# dm648_cslr_aemif register map
Vendor: Texas Instruments
Peripheral module from a debugger description file.
Registers are 32-bit, access not given, reset 0x0 unless marked. A register's access mark holds for its fields unless they carry their own. Offsets are as the file gives them; lines under a group give offsets from that group; [hi:lo] are bit positions; {n}, {i} and the like mark numbered series; 'fields as' and 'values as' point back to an identical list; <NAME> marks a mode.

## AEMIF — This module provides an interface between TI DSP device and SRAM devices
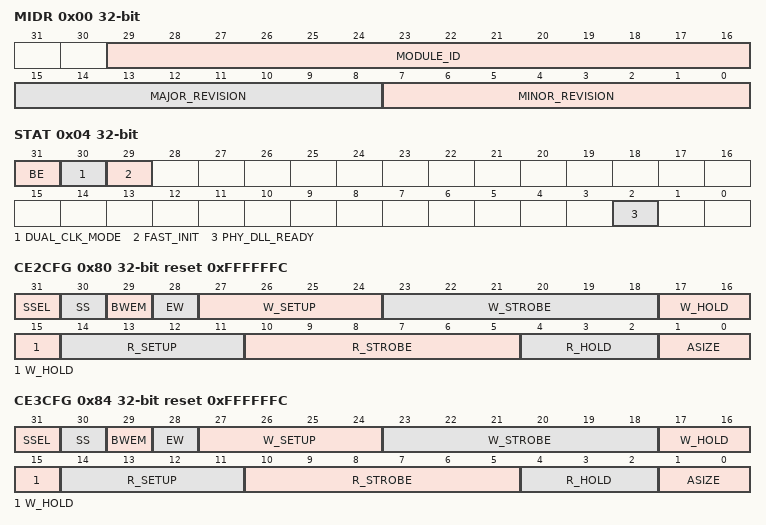
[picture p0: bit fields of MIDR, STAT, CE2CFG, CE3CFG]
0x00 MIDR — This register reflects the latest changes made to the memory controller.
  [29:16] MODULE_ID ro — EMIF module ID
  [15:8] MAJOR_REVISION ro
  [7:0] MINOR_REVISION ro
0x04 STAT — This register reflects the SDRAM status
  [31] BE ro — Big Endian. Reflects the value on the big_endian port that defines whether the EMIF is in big or little endian mode.
    1=B_ENDIAN (Big Endian); 0=L_ENDIAN (Little Endian)
  [30] DUAL_CLK_MODE ro — Dual Clock mode. Reflects the value on the dual_clk_mode port that defines whether the vclk and mclk inputs are asynchronous.
    1=ASYNC (vclk and mclk inputs are asynchronous.); 0=SYNC (vclk and mclk inputs are synchronous.)
  [29] FAST_INIT ro — the value on the fast_init port that defines whether the EMIF fast initialization mode has been enabled.
    0=NORMAL (normal operation); 1=TEST (running SDRAM functional tests.)
  [2] PHY_DLL_READY ro — DDR PHY Ready. Reflects the value on the phy_ready port (active high) that defines whether the DDR PHY is ready for normal operation.
    0=DEASSERTED (Signal deasserted); 1=ASSERTED (Signal asserted)
0x20 BPRIO reset 0xFF — Priority Raise Old Counter.
  [7:0] PR_OLD_COUNT rw — Number of memory transfers after which the EMIF momentarily raises the priority of oldcommands in the VBUSM Command FIFO.
0x80 CE2CFG rw reset 0xFFFFFFC — CS2 ASYNC Emif Register
  [31] SSEL — Synchronous or Async Memory select
    0=ASYNC_MEM (Asynchronous Memory); 1=SYNC_MEM (Synchronous Memory)
  [30] SS — Select Strobe Mode
    0=SELSTRB_DISABLE (Select Strobe Mode Disable); 1=SELSTRB_ENALBE (Select Strobe Mode Enable)
  [29] BWEM — Select WE Strobe Mode.
    0=BYTE_ENABLES (Low byte Enables); 1=BYTE_WRITE_ENABLES (Low Byte Write Enables)
  [28] EW — Extended Wait Mode
    0=EXT_WAIT_DISABLE (Extended Wait Mode Disabled); 1=EXT_WAIT_ENABLE (Extended Wait Mode Enabled)
  [27:24] W_SETUP — Write Strobe Setup cycles.
  [23:18] W_STROBE — Write Strobe Duration Cycles
  [17:15] W_HOLD — Write Strobe Hold Cycles
  [14:11] R_SETUP — Read Strobe Setup Cycles
  [10:5] R_STROBE — Read Strobe Duration Cycles
  [4:2] R_HOLD — Read Strobe Hold Cycles
  [1:0] ASIZE — Asynchronous Memory Size
    0=8BIT (8 bit data bus); 1=16BIT (16 bit data bus); 2=32BIT (32 bit data bus); 3=64BIT (64 bit data bus)
0x84 CE3CFG rw reset 0xFFFFFFC — CS3 ASYNC Emif Register
  [31] SSEL — Synchronous or Async Memory select
    values as CE2CFG.SSEL
  [30] SS — Select Strobe Mode
    values as CE2CFG.SS
  [29] BWEM — Select WE Strobe Mode.
    values as CE2CFG.BWEM
  [28] EW — Extended Wait Mode
    values as CE2CFG.EW
  [27:24] W_SETUP — Write Strobe Setup cycles.
  [23:18] W_STROBE — Write Strobe Duration Cycles
  [17:15] W_HOLD — Write Strobe Hold Cycles
  [14:11] R_SETUP — Read Strobe Setup Cycles
  [10:5] R_STROBE — Read Strobe Duration Cycles
  [4:2] R_HOLD — Read Strobe Hold Cycles
  [1:0] ASIZE — Asynchronous Memory Size
    0=8BIT (8 bit data bus); 1=16BIT (16 bit data bus); 3=64BIT (64 bit data bus)
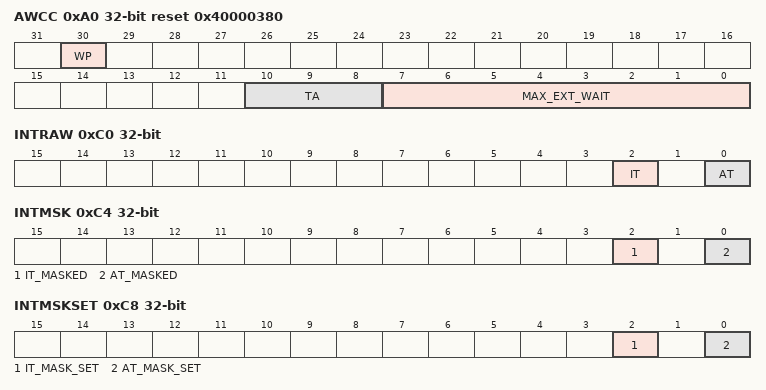
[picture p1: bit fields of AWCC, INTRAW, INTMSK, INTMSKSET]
0xA0 AWCC reset 0x40000380 — ASYNC Wait Cycle Config Register
  [30] WP rw — Wait Polarity
    0=WAIT_ONLOW (Wait till signal mwait_I goes low)
  [10:8] TA rw — Turn Around cycles
  [7:0] MAX_EXT_WAIT rw — Maximum Extended Wait Cycles
0xC0 INTRAW
  [2] IT rw — Line Trap. Set to 1 by hardware to indicate illegal memory access type. Writing a 1 will clear this bit as well as the lt_masked bit in the Interrupt Masked register. Writing a 0 has no effect.
    1=CLEAR
  [0] AT rw — Asynchronous Timeout.
0xC4 INTMSK
  [2] IT_MASKED rw — Masked Line Trap. Set to 1 by hardware to indicate illegal memory access type, only if the lt_mask_set bit in the Interrupt Mask Set Register is set to 1. Writing a 1 will clear this bit as well as the lt bit in the Interrupt Raw register. Writing a 0 has no effect.
    1=CLEAR
  [0] AT_MASKED rw — Masked Asynchronous Timeout.
0xC8 INTMSKSET
  [2] IT_MASK_SET rw — Mask set for lt_masked bit in the Interrupt Masked Register. Writing a 1 will enable the interrupt, and set this bit as well as the lt_mask_clr bit in the Interrupt Mask Clear register. The interrupt will not be enabled, and this bit as well as the lt_mask_clr bit will not be set if a 1 is written to this bit and the lt_mask_clr bit at the same time. Writing a 0 has no effect.
    1=SET
  [0] AT_MASK_SET rw — Mask set for at_masked bit in the Interrupt Masked Register.
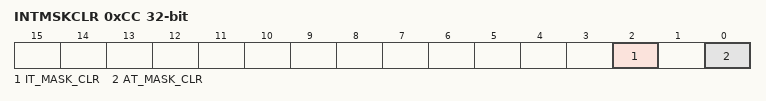
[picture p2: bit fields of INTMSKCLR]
0xCC INTMSKCLR
  [2] IT_MASK_CLR rw — Mask clear for lt_masked bit in the Interrupt Masked Register. Writing a 1 will disable the interrupt, and clear this bit as well as the lt_mask_set bit in the Interrupt Mask Set register. Writing a 0 has no effect.
    1=CLEAR
  [0] AT_MASK_CLR rw — Mask clear for at_masked bit in the Interrupt Masked Register.
